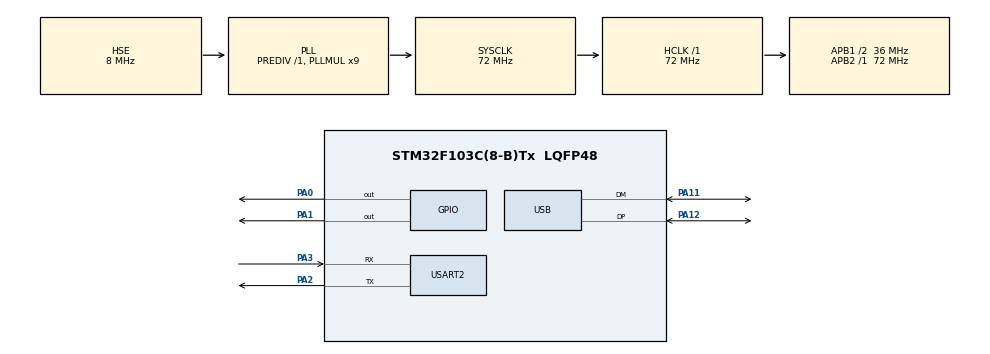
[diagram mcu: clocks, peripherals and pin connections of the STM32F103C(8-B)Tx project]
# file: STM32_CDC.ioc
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Dma.Request0=USART2_TX
Dma.Request1=USART2_RX
Dma.USART2_RX.1.Direction=DMA_PERIPH_TO_MEMORY
Dma.USART2_RX.1.Instance=DMA1_Channel6
Dma.USART2_RX.1.MemDataAlignment=DMA_MDATAALIGN_BYTE
Dma.USART2_RX.1.MemInc=DMA_MINC_ENABLE
Dma.USART2_RX.1.Mode=DMA_NORMAL
Dma.USART2_RX.1.PeriphDataAlignment=DMA_PDATAALIGN_BYTE
Dma.USART2_RX.1.PeriphInc=DMA_PINC_DISABLE
Dma.USART2_RX.1.Priority=DMA_PRIORITY_LOW
Dma.USART2_TX.0.Direction=DMA_MEMORY_TO_PERIPH
Dma.USART2_TX.0.Instance=DMA1_Channel7
Dma.USART2_TX.0.MemDataAlignment=DMA_MDATAALIGN_BYTE
Dma.USART2_TX.0.MemInc=DMA_MINC_ENABLE
Dma.USART2_TX.0.Mode=DMA_NORMAL
Dma.USART2_TX.0.PeriphDataAlignment=DMA_PDATAALIGN_BYTE
Dma.USART2_TX.0.PeriphInc=DMA_PINC_DISABLE
Dma.USART2_TX.0.Priority=DMA_PRIORITY_LOW
Mcu.Family=STM32F1
Mcu.Name=STM32F103C(8-B)Tx
Mcu.Package=LQFP48
NVIC.DMA1_Channel6_IRQn=true\:1\:0\:true\:false\:true\:false\:true
NVIC.DMA1_Channel7_IRQn=true\:1\:0\:true\:false\:true\:false\:true
NVIC.PriorityGroup=NVIC_PRIORITYGROUP_4
NVIC.USART2_IRQn=true\:1\:0\:true\:false\:true\:true\:true
NVIC.USB_LP_CAN1_RX0_IRQn=true\:2\:0\:true\:false\:true\:false\:true
PA0-WKUP.GPIO_ModeDefaultOutputPP=GPIO_MODE_OUTPUT_OD
PA0-WKUP.Signal=GPIO_Output
PA1.GPIO_ModeDefaultOutputPP=GPIO_MODE_OUTPUT_OD
PA1.Signal=GPIO_Output
PA11.Mode=Device
PA11.Signal=USB_DM
PA12.Mode=Device
PA12.Signal=USB_DP
PA13.Mode=Serial_Wire
PA13.Signal=SYS_JTMS-SWDIO
PA14.Mode=Serial_Wire
PA14.Signal=SYS_JTCK-SWCLK
PA2.Mode=Asynchronous
PA2.Signal=USART2_TX
PA3.Mode=Asynchronous
PA3.Signal=USART2_RX
PD0-OSC_IN.Mode=HSE-External-Oscillator
PD0-OSC_IN.Signal=RCC_OSC_IN
PD1-OSC_OUT.Mode=HSE-External-Oscillator
PD1-OSC_OUT.Signal=RCC_OSC_OUT
ProjectManager.HeapSize=0x200
ProjectManager.StackSize=0x400
ProjectManager.TargetToolchain=STM32CubeIDE
RCC.AHBFreq_Value=72000000
RCC.APB1CLKDivider=RCC_HCLK_DIV2
RCC.APB1Freq_Value=36000000
RCC.APB1TimFreq_Value=72000000
RCC.APB2Freq_Value=72000000
RCC.APB2TimFreq_Value=72000000
RCC.HCLKFreq_Value=72000000
RCC.PLLMUL=RCC_PLL_MUL9
RCC.SYSCLKFreq_VALUE=72000000
RCC.SYSCLKSource=RCC_SYSCLKSOURCE_PLLCLK
RCC.USBFreq_Value=48000000
RCC.USBPrescaler=RCC_USBCLKSOURCE_PLL_DIV1_5
USART2.VirtualMode=VM_ASYNC
USB_DEVICE.APP_RX_DATA_SIZE=512
USB_DEVICE.APP_TX_DATA_SIZE=512
USB_DEVICE.CLASS_NAME_FS=CDC
USB_DEVICE.VirtualMode=Cdc
USB_DEVICE.VirtualModeFS=Cdc_FS
VP_USB_DEVICE_VS_USB_DEVICE_CDC_FS.Mode=CDC_FS
board=custom

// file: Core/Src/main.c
/* USER CODE BEGIN Header */
/**
 ******************************************************************************
 * @file           : main.c
 * @brief          : Main program body
 ******************************************************************************
 * @attention
 *
 * <h2><center>&copy; Copyright (c) 2019 STMicroelectronics.
 * All rights reserved.</center></h2>
 *
 * This software component is licensed by ST under BSD 3-Clause license,
 * the "License"; You may not use this file except in compliance with the
 * License. You may obtain a copy of the License at:
 *                        opensource.org/licenses/BSD-3-Clause
 *
 ******************************************************************************
 */
/* USER CODE END Header */

#include "main.h"
#include "usb_device.h"

UART_HandleTypeDef huart2;
DMA_HandleTypeDef hdma_usart2_tx;
DMA_HandleTypeDef hdma_usart2_rx;

/* USER CODE BEGIN PV */
uint32_t systick;
/* USER CODE END PV */

void SystemClock_Config(void);
static void MX_GPIO_Init(void);
static void MX_USART2_UART_Init(void);
static void MX_DMA_Init(void);

int main(void)
{

  /* MCU Configuration--------------------------------------------------------*/

  /* Reset of all peripherals, Initializes the Flash interface and the Systick. */
  HAL_Init();

  /* Configure the system clock */
  SystemClock_Config();

  /* Initialize all configured peripherals */
  MX_GPIO_Init();
  MX_USART2_UART_Init();
  MX_USB_DEVICE_Init();
  MX_DMA_Init();

  /* Infinite loop */
	while (1) {
	if(systick) {
		systick = 0;
		if (huart2.Instance->SR & UART_FLAG_IDLE && hdma_usart2_rx.State == HAL_DMA_STATE_BUSY) /* if Idle flag is set */
				{
					volatile uint32_t tmp; /* Must be volatile to prevent optimizations */
					tmp = huart2.Instance->SR; /* Read status register */
					tmp = huart2.Instance->DR; /* Read data register */ //This two reads clears the IDLE Flag

					uint32_t cndtr = huart2.hdmarx->Instance->CNDTR;
					if(cndtr < 256) {
						HAL_UART_AbortReceive(&huart2);
						UART_Early_Exit(&huart2, cndtr);
					}
				}
	}
	}
}

void SystemClock_Config(void)
{
  RCC_OscInitTypeDef RCC_OscInitStruct = {0};
  RCC_ClkInitTypeDef RCC_ClkInitStruct = {0};
  RCC_PeriphCLKInitTypeDef PeriphClkInit = {0};

  /** Initializes the CPU, AHB and APB busses clocks
  */
  RCC_OscInitStruct.OscillatorType = RCC_OSCILLATORTYPE_HSE;
  RCC_OscInitStruct.HSEState = RCC_HSE_ON;
  RCC_OscInitStruct.HSEPredivValue = RCC_HSE_PREDIV_DIV1;
  RCC_OscInitStruct.HSIState = RCC_HSI_ON;
  RCC_OscInitStruct.PLL.PLLState = RCC_PLL_ON;
  RCC_OscInitStruct.PLL.PLLSource = RCC_PLLSOURCE_HSE;
  RCC_OscInitStruct.PLL.PLLMUL = RCC_PLL_MUL9;
  if (HAL_RCC_OscConfig(&RCC_OscInitStruct) != HAL_OK)
  {
    Error_Handler();
  }
  /** Initializes the CPU, AHB and APB busses clocks
  */
  RCC_ClkInitStruct.ClockType = RCC_CLOCKTYPE_HCLK|RCC_CLOCKTYPE_SYSCLK
                              |RCC_CLOCKTYPE_PCLK1|RCC_CLOCKTYPE_PCLK2;
  RCC_ClkInitStruct.SYSCLKSource = RCC_SYSCLKSOURCE_PLLCLK;
  RCC_ClkInitStruct.AHBCLKDivider = RCC_SYSCLK_DIV1;
  RCC_ClkInitStruct.APB1CLKDivider = RCC_HCLK_DIV2;
  RCC_ClkInitStruct.APB2CLKDivider = RCC_HCLK_DIV1;

  if (HAL_RCC_ClockConfig(&RCC_ClkInitStruct, FLASH_LATENCY_2) != HAL_OK)
  {
    Error_Handler();
  }
  PeriphClkInit.PeriphClockSelection = RCC_PERIPHCLK_USB;
  PeriphClkInit.UsbClockSelection = RCC_USBCLKSOURCE_PLL_DIV1_5;
  if (HAL_RCCEx_PeriphCLKConfig(&PeriphClkInit) != HAL_OK)
  {
    Error_Handler();
  }
}

static void MX_USART2_UART_Init(void)
{

  /* USER CODE BEGIN USART2_Init 0 */
	return;	//Dont init uart here. We do that in the CDC code
  /* USER CODE END USART2_Init 0 */

  huart2.Instance = USART2;
  huart2.Init.BaudRate = 115200;
  huart2.Init.WordLength = UART_WORDLENGTH_8B;
  huart2.Init.StopBits = UART_STOPBITS_1;
  huart2.Init.Parity = UART_PARITY_NONE;
  huart2.Init.Mode = UART_MODE_TX_RX;
  huart2.Init.HwFlowCtl = UART_HWCONTROL_NONE;
  huart2.Init.OverSampling = UART_OVERSAMPLING_16;
  if (HAL_UART_Init(&huart2) != HAL_OK)
  {
    Error_Handler();
  }

}

static void MX_DMA_Init(void)
{

  /* DMA controller clock enable */
  __HAL_RCC_DMA1_CLK_ENABLE();

  /* DMA interrupt init */
  /* DMA1_Channel6_IRQn interrupt configuration */
  HAL_NVIC_SetPriority(DMA1_Channel6_IRQn, 1, 0);
  HAL_NVIC_EnableIRQ(DMA1_Channel6_IRQn);
  /* DMA1_Channel7_IRQn interrupt configuration */
  HAL_NVIC_SetPriority(DMA1_Channel7_IRQn, 1, 0);
  HAL_NVIC_EnableIRQ(DMA1_Channel7_IRQn);

}

static void MX_GPIO_Init(void)
{
  GPIO_InitTypeDef GPIO_InitStruct = {0};

  /* GPIO Ports Clock Enable */
  __HAL_RCC_GPIOD_CLK_ENABLE();
  __HAL_RCC_GPIOA_CLK_ENABLE();

  /*Configure GPIO pin Output Level */
  HAL_GPIO_WritePin(GPIOA, GPIO_PIN_0|GPIO_PIN_1, GPIO_PIN_RESET);

  /*Configure GPIO pins : PA0 PA1 */
  GPIO_InitStruct.Pin = GPIO_PIN_0|GPIO_PIN_1;
  GPIO_InitStruct.Mode = GPIO_MODE_OUTPUT_OD;
  GPIO_InitStruct.Pull = GPIO_NOPULL;
  GPIO_InitStruct.Speed = GPIO_SPEED_FREQ_LOW;
  HAL_GPIO_Init(GPIOA, &GPIO_InitStruct);

}

void Error_Handler(void)
{
}

/************************ (C) COPYRIGHT STMicroelectronics *****END OF FILE****/
